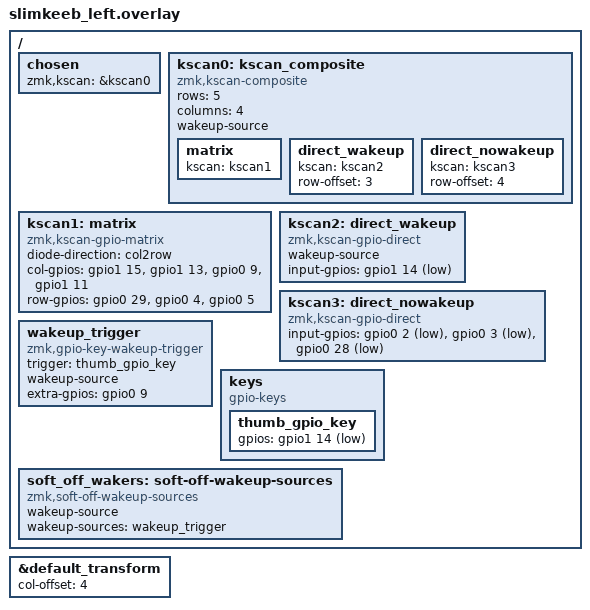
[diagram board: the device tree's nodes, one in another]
#include "slimkeeb.dtsi"

/ {
    chosen {
        zmk,kscan = &kscan0;
    };

    kscan0: kscan_composite {
        compatible = "zmk,kscan-composite";
        rows = <5>;
        columns = <4>;
        wakeup-source;  // composite 전체에 추가 (deep/soft off 안정성 ↑)
        matrix {
            kscan = <&kscan1>;
        };
        direct_wakeup {
            kscan = <&kscan2>;
            row-offset = <3>;
        };
        direct_nowakeup {
            kscan = <&kscan3>;
            row-offset = <4>;
        };
    };

    kscan1: matrix {
        compatible = "zmk,kscan-gpio-matrix";
        diode-direction = "col2row";
        col-gpios
            = <&gpio1 15 GPIO_ACTIVE_HIGH>
            , <&gpio1 13 GPIO_ACTIVE_HIGH>
            , <&gpio0  9 GPIO_ACTIVE_HIGH>
            , <&gpio1 11 GPIO_ACTIVE_HIGH>
            ;
        row-gpios
            = <&gpio0 29 (GPIO_ACTIVE_HIGH | GPIO_PULL_DOWN)>
            , <&gpio0  4 (GPIO_ACTIVE_HIGH | GPIO_PULL_DOWN)>
            , <&gpio0  5 (GPIO_ACTIVE_HIGH | GPIO_PULL_DOWN)>
            ;
    };

    kscan2: direct_wakeup {
        compatible = "zmk,kscan-gpio-direct";
        wakeup-source;  // 필수!
        input-gpios =
            <&gpio1 14 (GPIO_ACTIVE_LOW | GPIO_PULL_UP)>;  // left T3 하나만!
    };

    kscan3: direct_nowakeup {
        compatible = "zmk,kscan-gpio-direct";
        input-gpios =
            <&gpio0  2 (GPIO_ACTIVE_LOW | GPIO_PULL_UP)>,
            <&gpio0  3 (GPIO_ACTIVE_LOW | GPIO_PULL_UP)>,
            <&gpio0 28 (GPIO_ACTIVE_LOW | GPIO_PULL_UP)>;
    };

wakeup_trigger: wakeup_trigger {
        compatible = "zmk,gpio-key-wakeup-trigger";
        trigger = <&thumb_gpio_key>;
        wakeup-source;

        extra-gpios = <&gpio0 9 GPIO_ACTIVE_HIGH>;  // left T3 column (대칭상 gpio0 9로 가정, 필요 시 변경)
    };

    keys {
        compatible = "gpio-keys";
        thumb_gpio_key: thumb_gpio_key {
            gpios = <&gpio1 14 (GPIO_ACTIVE_LOW | GPIO_PULL_UP)>;
        };
    };

    // 수정 핵심: property 이름을 wakeup-sources로!
    soft_off_wakers: soft-off-wakeup-sources {
        compatible = "zmk,soft-off-wakeup-sources";
        wakeup-source;
        wakeup-sources = <&wakeup_trigger>;  // ← wakers → wakeup-sources로 변경!
    };
};

&default_transform {
    col-offset = <4>;  // 필요 시 유지 (left/right 공통 transform)
};
